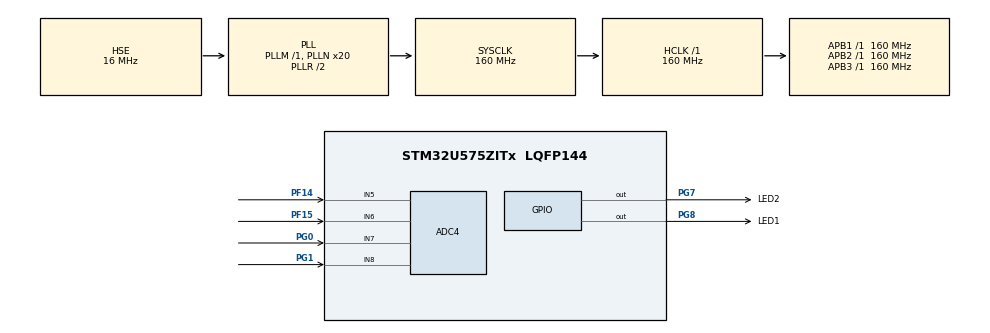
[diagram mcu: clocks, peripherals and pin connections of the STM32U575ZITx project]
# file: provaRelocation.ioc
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ADC4.Channel-0\#ChannelRegularConversion=ADC_CHANNEL_5
ADC4.ClockPrescaler=ADC_CLOCK_ASYNC_DIV256
ADC4.NbrOfConversion=1
ADC4.NbrOfConversionFlag=1
ADC4.OffsetNumber-0\#ChannelRegularConversion=ADC_OFFSET_NONE
ADC4.Rank-0\#ChannelRegularConversion=1
ADC4.RankArg-0\#ChannelRegularConversion=ADC4_REGULAR_RANK_1
ADC4.SamplingTime-0\#ChannelRegularConversion=ADC4_SAMPLINGTIME_COMMON_1
ADC4.SelectedChannel=ADC_CHANNEL_5|ADC_CHANNEL_6|ADC_CHANNEL_7|ADC_CHANNEL_8
ADC4.Sequencer=FULLY_CONFIGURABLE
CORTEX_M33_NS.userName=CORTEX_M33
Mcu.Family=STM32U5
Mcu.Name=STM32U575ZITx
Mcu.Package=LQFP144
NVIC.ADC4_IRQn=true\:0\:0\:false\:false\:true\:true\:true\:true
NVIC.PriorityGroup=NVIC_PRIORITYGROUP_4
NVIC.TIM6_IRQn=true\:0\:0\:false\:false\:true\:true\:true\:true
PF14.Mode=IN5
PF14.Signal=ADC4_IN5
PF15.Mode=IN6
PF15.Signal=ADC4_IN6
PG0.Mode=IN7
PG0.Signal=ADC4_IN7
PG1.Mode=IN8
PG1.Signal=ADC4_IN8
PG7.GPIO_Label=LED2
PG7.GPIO_ModeDefaultOutputPP=GPIO_MODE_OUTPUT_PP
PG7.GPIO_PuPd=GPIO_NOPULL
PG7.GPIO_Speed=GPIO_SPEED_FREQ_LOW
PG7.PinState=GPIO_PIN_RESET
PG7.Signal=GPIO_Output
PG8.GPIO_Label=LED1
PG8.GPIO_ModeDefaultOutputPP=GPIO_MODE_OUTPUT_PP
PG8.GPIO_PuPd=GPIO_NOPULL
PG8.GPIO_Speed=GPIO_SPEED_FREQ_LOW
PG8.PinState=GPIO_PIN_RESET
PG8.Signal=GPIO_Output
PH0-OSC_IN\ (PH0).Mode=HSE-External-Oscillator
PH0-OSC_IN\ (PH0).Signal=RCC_OSC_IN
PH1-OSC_OUT\ (PH1).Mode=HSE-External-Oscillator
PH1-OSC_OUT\ (PH1).Signal=RCC_OSC_OUT
ProjectManager.HeapSize=0x200
ProjectManager.StackSize=0x400
ProjectManager.TargetToolchain=STM32CubeIDE
RCC.ADCFreq_Value=16000000
RCC.AHBFreq_Value=160000000
RCC.APB1Freq_Value=160000000
RCC.APB1TimFreq_Value=160000000
RCC.APB2Freq_Value=160000000
RCC.APB2TimFreq_Value=160000000
RCC.APB3Freq_Value=160000000
RCC.CortexFreq_Value=160000000
RCC.EPOD_VALUE=16000000
RCC.FLatency=FLASH_LATENCY_4
RCC.HCLKFreq_Value=160000000
RCC.HSE_VALUE=16000000
RCC.HSI48_VALUE=48000000
RCC.HSI_VALUE=16000000
RCC.LSE_VALUE=32768
RCC.LSIDIV_VALUE=32000
RCC.MSI_VALUE=4000000
RCC.PLLN=20
RCC.PLLSourceVirtual=RCC_PLLSOURCE_HSE
RCC.PWR_Regulator_Voltage_Scale=PWR_REGULATOR_VOLTAGE_SCALE1
RCC.SYSCLKFreq_VALUE=160000000
RCC.SYSCLKSource=RCC_SYSCLKSOURCE_PLLCLK
RCC.USBFreq_Value=48000000
RCC.VCOOutputFreq_Value=320000000
TIM6.PeriodNoDither=500
TIM6.Prescaler=160
VP_IWDG_VS_IWDG.Mode=IWDG_Activate
VP_LPBAMQUEUE_VS_QUEUE.Mode=QUEUEMODE
VP_LPBAM_VS_SIG1.Mode=SmartRun
VP_LPBAM_VS_SIG4.Mode=LPDMA1
VP_MEMORYMAP_VS_MEMORYMAP.Mode=CurAppReg
VP_PWR_VS_SECSignals.Mode=Security/Privilege
VP_PWR_Vdda.Mode=isolationVdda
VP_TIM6_VS_ClockSourceINT.Mode=Enable_Timer
board=custom

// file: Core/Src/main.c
/* USER CODE BEGIN Header */
/**
  ******************************************************************************
  * @file           : main.c
  * @brief          : Main program body
  ******************************************************************************
  * @attention
  *
  * Copyright (c) 2023 STMicroelectronics.
  * All rights reserved.
  *
  * This software is licensed under terms that can be found in the LICENSE file
  * in the root directory of this software component.
  * If no LICENSE file comes with this software, it is provided AS-IS.
  *
  ******************************************************************************
  */
/* USER CODE END Header */
#include "main.h"

ADC_HandleTypeDef hadc4;

IWDG_HandleTypeDef hiwdg;

TIM_HandleTypeDef htim6;

void SystemClock_Config(void);
static void MX_GPIO_Init(void);
static void MX_MEMORYMAP_Init(void);
static void MX_ADC4_Init(void);
static void MX_IWDG_Init(void);
static void MX_TIM6_Init(void);

int main(void)
{

  /* MCU Configuration--------------------------------------------------------*/

  /* Reset of all peripherals, Initializes the Flash interface and the Systick. */
  HAL_Init();

  /* Configure the system clock */
  SystemClock_Config();

  /* Initialize all configured peripherals */
  MX_GPIO_Init();
  MX_MEMORYMAP_Init();
  MX_ADC4_Init();
  MX_IWDG_Init();
  MX_TIM6_Init();
  /* USER CODE BEGIN 2 */
  HAL_TIM_Base_Start_IT(&htim6);
  /* USER CODE END 2 */

  /* Infinite loop */
  /* USER CODE BEGIN WHILE */
  while (1)
  {
	  HAL_IWDG_Refresh(&hiwdg);
    /* USER CODE END WHILE */

  }
}

void SystemClock_Config(void)
{
  RCC_OscInitTypeDef RCC_OscInitStruct = {0};
  RCC_ClkInitTypeDef RCC_ClkInitStruct = {0};

  /** Configure the main internal regulator output voltage
  */
  if (HAL_PWREx_ControlVoltageScaling(PWR_REGULATOR_VOLTAGE_SCALE1) != HAL_OK)
  {
    Error_Handler();
  }

  /** Initializes the CPU, AHB and APB buses clocks
  */
  RCC_OscInitStruct.OscillatorType = RCC_OSCILLATORTYPE_HSI|RCC_OSCILLATORTYPE_LSI
                              |RCC_OSCILLATORTYPE_HSE;
  RCC_OscInitStruct.HSEState = RCC_HSE_ON;
  RCC_OscInitStruct.HSIState = RCC_HSI_ON;
  RCC_OscInitStruct.HSICalibrationValue = RCC_HSICALIBRATION_DEFAULT;
  RCC_OscInitStruct.LSIState = RCC_LSI_ON;
  RCC_OscInitStruct.LSIDiv = RCC_LSI_DIV1;
  RCC_OscInitStruct.PLL.PLLState = RCC_PLL_ON;
  RCC_OscInitStruct.PLL.PLLSource = RCC_PLLSOURCE_HSE;
  RCC_OscInitStruct.PLL.PLLMBOOST = RCC_PLLMBOOST_DIV1;
  RCC_OscInitStruct.PLL.PLLM = 1;
  RCC_OscInitStruct.PLL.PLLN = 20;
  RCC_OscInitStruct.PLL.PLLP = 2;
  RCC_OscInitStruct.PLL.PLLQ = 2;
  RCC_OscInitStruct.PLL.PLLR = 2;
  RCC_OscInitStruct.PLL.PLLRGE = RCC_PLLVCIRANGE_1;
  RCC_OscInitStruct.PLL.PLLFRACN = 0;
  if (HAL_RCC_OscConfig(&RCC_OscInitStruct) != HAL_OK)
  {
    Error_Handler();
  }

  /** Initializes the CPU, AHB and APB buses clocks
  */
  RCC_ClkInitStruct.ClockType = RCC_CLOCKTYPE_HCLK|RCC_CLOCKTYPE_SYSCLK
                              |RCC_CLOCKTYPE_PCLK1|RCC_CLOCKTYPE_PCLK2
                              |RCC_CLOCKTYPE_PCLK3;
  RCC_ClkInitStruct.SYSCLKSource = RCC_SYSCLKSOURCE_PLLCLK;
  RCC_ClkInitStruct.AHBCLKDivider = RCC_SYSCLK_DIV1;
  RCC_ClkInitStruct.APB1CLKDivider = RCC_HCLK_DIV1;
  RCC_ClkInitStruct.APB2CLKDivider = RCC_HCLK_DIV1;
  RCC_ClkInitStruct.APB3CLKDivider = RCC_HCLK_DIV1;

  if (HAL_RCC_ClockConfig(&RCC_ClkInitStruct, FLASH_LATENCY_4) != HAL_OK)
  {
    Error_Handler();
  }
}

static void MX_ADC4_Init(void)
{

  ADC_ChannelConfTypeDef sConfig = {0};

  /** Common config
  */
  hadc4.Instance = ADC4;
  hadc4.Init.ClockPrescaler = ADC_CLOCK_ASYNC_DIV256;
  hadc4.Init.Resolution = ADC_RESOLUTION_12B;
  hadc4.Init.DataAlign = ADC_DATAALIGN_RIGHT;
  hadc4.Init.ScanConvMode = ADC4_SCAN_DISABLE;
  hadc4.Init.EOCSelection = ADC_EOC_SINGLE_CONV;
  hadc4.Init.LowPowerAutoPowerOff = ADC_LOW_POWER_NONE;
  hadc4.Init.LowPowerAutoWait = DISABLE;
  hadc4.Init.ContinuousConvMode = DISABLE;
  hadc4.Init.NbrOfConversion = 1;
  hadc4.Init.DiscontinuousConvMode = DISABLE;
  hadc4.Init.ExternalTrigConv = ADC_SOFTWARE_START;
  hadc4.Init.ExternalTrigConvEdge = ADC_EXTERNALTRIGCONVEDGE_NONE;
  hadc4.Init.DMAContinuousRequests = DISABLE;
  hadc4.Init.TriggerFrequencyMode = ADC_TRIGGER_FREQ_LOW;
  hadc4.Init.Overrun = ADC_OVR_DATA_PRESERVED;
  hadc4.Init.SamplingTimeCommon1 = ADC4_SAMPLETIME_1CYCLE_5;
  hadc4.Init.SamplingTimeCommon2 = ADC4_SAMPLETIME_1CYCLE_5;
  hadc4.Init.OversamplingMode = DISABLE;
  if (HAL_ADC_Init(&hadc4) != HAL_OK)
  {
    Error_Handler();
  }

  /** Configure Regular Channel
  */
  sConfig.Channel = ADC_CHANNEL_5;
  sConfig.Rank = ADC4_REGULAR_RANK_1;
  sConfig.SamplingTime = ADC4_SAMPLINGTIME_COMMON_1;
  sConfig.OffsetNumber = ADC_OFFSET_NONE;
  sConfig.Offset = 0;
  if (HAL_ADC_ConfigChannel(&hadc4, &sConfig) != HAL_OK)
  {
    Error_Handler();
  }
  /* USER CODE BEGIN ADC4_Init 2 */

  //HAL_ADC_Start_IT(&hadc4);
  /* USER CODE END ADC4_Init 2 */

}

static void MX_IWDG_Init(void)
{

  hiwdg.Instance = IWDG;
  hiwdg.Init.Prescaler = IWDG_PRESCALER_4;
  hiwdg.Init.Window = 4095;
  hiwdg.Init.Reload = 4095;
  hiwdg.Init.EWI = 0;
  if (HAL_IWDG_Init(&hiwdg) != HAL_OK)
  {
    Error_Handler();
  }

}

static void MX_MEMORYMAP_Init(void)
{

}

static void MX_TIM6_Init(void)
{

  TIM_MasterConfigTypeDef sMasterConfig = {0};

  htim6.Instance = TIM6;
  htim6.Init.Prescaler = 160;
  htim6.Init.CounterMode = TIM_COUNTERMODE_UP;
  htim6.Init.Period = 500;
  htim6.Init.AutoReloadPreload = TIM_AUTORELOAD_PRELOAD_DISABLE;
  if (HAL_TIM_Base_Init(&htim6) != HAL_OK)
  {
    Error_Handler();
  }
  sMasterConfig.MasterOutputTrigger = TIM_TRGO_RESET;
  sMasterConfig.MasterSlaveMode = TIM_MASTERSLAVEMODE_DISABLE;
  if (HAL_TIMEx_MasterConfigSynchronization(&htim6, &sMasterConfig) != HAL_OK)
  {
    Error_Handler();
  }

}

static void MX_GPIO_Init(void)
{
  GPIO_InitTypeDef GPIO_InitStruct = {0};

  /* GPIO Ports Clock Enable */
  __HAL_RCC_GPIOH_CLK_ENABLE();
  __HAL_RCC_GPIOF_CLK_ENABLE();
  __HAL_RCC_GPIOG_CLK_ENABLE();

  /*Configure GPIO pin Output Level */
  HAL_GPIO_WritePin(GPIOG, LED2_Pin|LED1_Pin, GPIO_PIN_RESET);

  /*Configure GPIO pins : LED2_Pin LED1_Pin */
  GPIO_InitStruct.Pin = LED2_Pin|LED1_Pin;
  GPIO_InitStruct.Mode = GPIO_MODE_OUTPUT_PP;
  GPIO_InitStruct.Pull = GPIO_NOPULL;
  GPIO_InitStruct.Speed = GPIO_SPEED_FREQ_LOW;
  HAL_GPIO_Init(GPIOG, &GPIO_InitStruct);

}

void Error_Handler(void)
{
  __disable_irq();
  while (1)
  {
  }
}
